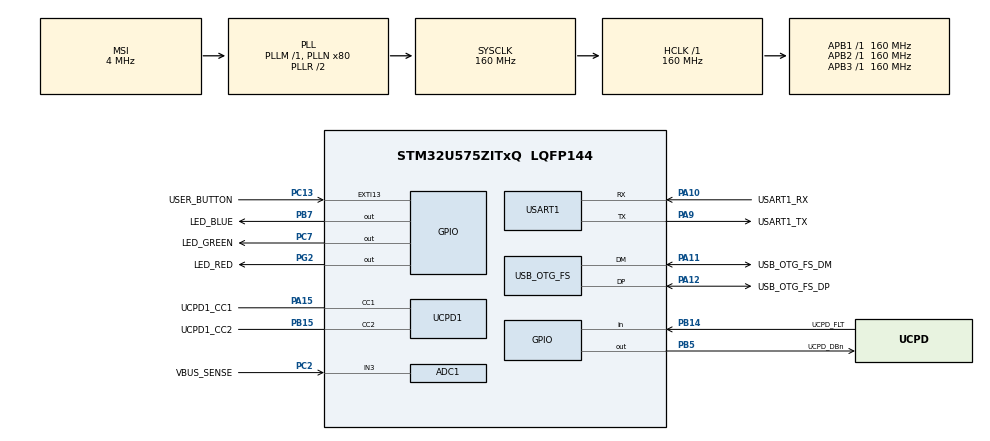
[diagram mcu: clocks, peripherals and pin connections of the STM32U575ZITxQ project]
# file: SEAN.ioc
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ADC1.NbrOfConversion=1
ADC1.Resolution=ADC_RESOLUTION_14B
ADC1.master=1
CORTEX_M33_NS.userName=CORTEX_M33
Mcu.Family=STM32U5
Mcu.Name=STM32U575ZITxQ
Mcu.Package=LQFP144
NVIC.OTG_FS_IRQn=true\:0\:0\:false\:false\:true\:false\:true\:true\:true
NVIC.PriorityGroup=NVIC_PRIORITYGROUP_3
NVIC.TIM1_UP_IRQn=true\:7\:0\:false\:false\:true\:false\:false\:true\:true
NVIC.TIM4_IRQn=true\:0\:0\:false\:false\:true\:false\:true\:true\:true
NVIC.TimeBase=TIM1_UP_IRQn
NVIC.TimeBaseIP=TIM1
PA10.GPIO_Label=USART1_RX
PA10.GPIO_PuPd=GPIO_PULLDOWN
PA10.GPIO_Speed=GPIO_SPEED_FREQ_VERY_HIGH
PA10.Mode=Asynchronous
PA10.Signal=USART1_RX
PA11.GPIO_Label=USB_OTG_FS_DM
PA11.GPIO_Speed=GPIO_SPEED_FREQ_VERY_HIGH
PA11.Mode=Device_Only
PA11.Signal=USB_OTG_FS_DM
PA12.GPIO_Label=USB_OTG_FS_DP
PA12.GPIO_Speed=GPIO_SPEED_FREQ_VERY_HIGH
PA12.Mode=Device_Only
PA12.Signal=USB_OTG_FS_DP
PA13\ (JTMS/SWDIO).Mode=Trace_Asynchronous_SW
PA13\ (JTMS/SWDIO).Signal=DEBUG_JTMS-SWDIO
PA14\ (JTCK/SWCLK).Mode=Trace_Asynchronous_SW
PA14\ (JTCK/SWCLK).Signal=DEBUG_JTCK-SWCLK
PA15\ (JTDI).GPIO_Label=UCPD1_CC1
PA15\ (JTDI).Mode=Sink_AllSignals
PA15\ (JTDI).Signal=UCPD1_CC1
PA9.GPIO_Label=USART1_TX
PA9.GPIO_PuPd=GPIO_PULLDOWN
PA9.GPIO_Speed=GPIO_SPEED_FREQ_VERY_HIGH
PA9.Mode=Asynchronous
PA9.Signal=USART1_TX
PB14.GPIO_Label=UCPD_FLT
PB14.Signal=GPIO_Input
PB15.GPIO_Label=UCPD1_CC2
PB15.Mode=Sink_AllSignals
PB15.Signal=UCPD1_CC2
PB3\ (JTDO/TRACESWO).Mode=Trace_Asynchronous_SW
PB3\ (JTDO/TRACESWO).Signal=DEBUG_JTDO-SWO
PB5.GPIO_Label=UCPD_DBn
PB5.Signal=GPIO_Output
PB7.GPIO_Label=LED_BLUE
PB7.GPIO_ModeDefaultOutputPP=GPIO_MODE_OUTPUT_PP
PB7.GPIO_PuPd=GPIO_PULLUP
PB7.GPIO_Speed=GPIO_SPEED_FREQ_HIGH
PB7.Signal=GPIO_Output
PC13.GPIO_Label=USER_BUTTON
PC13.GPIO_ModeDefaultEXTI=GPIO_MODE_IT_FALLING
PC13.Signal=GPXTI13
PC14-OSC32_IN\ (PC14).Mode=LSE-External-Oscillator
PC14-OSC32_IN\ (PC14).Signal=RCC_OSC32_IN
PC15-OSC32_OUT\ (PC15).Mode=LSE-External-Oscillator
PC15-OSC32_OUT\ (PC15).Signal=RCC_OSC32_OUT
PC2.GPIO_Label=VBUS_SENSE
PC2.Mode=IN3-Single-Ended
PC2.Signal=ADC1_IN3
PC7.GPIO_Label=LED_GREEN
PC7.GPIO_PuPd=GPIO_PULLUP
PC7.GPIO_Speed=GPIO_SPEED_FREQ_HIGH
PC7.Signal=GPIO_Output
PG2.GPIO_Label=LED_RED
PG2.GPIO_ModeDefaultOutputPP=GPIO_MODE_OUTPUT_PP
PG2.GPIO_PuPd=GPIO_PULLUP
PG2.GPIO_Speed=GPIO_SPEED_FREQ_HIGH
PG2.Signal=GPIO_Output
PWR.PowerMode=PWR_SMPS_SUPPLY
ProjectManager.HeapSize=0x200
ProjectManager.StackSize=0x400
ProjectManager.TargetToolchain=STM32CubeIDE
RCC.ADCFreq_Value=16000000
RCC.AHBFreq_Value=160000000
RCC.APB1Freq_Value=160000000
RCC.APB1TimFreq_Value=160000000
RCC.APB2Freq_Value=160000000
RCC.APB2TimFreq_Value=160000000
RCC.APB3Freq_Value=160000000
RCC.CortexFreq_Value=160000000
RCC.DACCLockSelectionVirtual=RCC_DAC1CLKSOURCE_LSI
RCC.DACCLockSelectionVirtualString=RCC_DAC1CLKSOURCE_LSI
RCC.EPOD_VALUE=4000000
RCC.HCLKFreq_Value=160000000
RCC.HSE_VALUE=16000000
RCC.HSI48_VALUE=48000000
RCC.HSI_VALUE=16000000
RCC.LSIDIV_VALUE=32000
RCC.MSI_VALUE=4000000
RCC.PLLN=80
RCC.SYSCLKFreq_VALUE=160000000
RCC.SYSCLKSource=RCC_SYSCLKSOURCE_PLLCLK
RCC.USBFreq_Value=48000000
RCC.VCOOutputFreq_Value=320000000
TIM4.PeriodNoDither=9999
TIM4.Prescaler=7999
USART1.VirtualMode-Asynchronous=VM_ASYNC
USB_OTG_FS.VirtualMode=Device_Only
VP_ICACHE_VS_ICACHE.Mode=DefaultMode
VP_LPBAMQUEUE_VS_QUEUE.Mode=QUEUEMODE
VP_LPBAM_VS_SIG1.Mode=SmartRun
VP_LPBAM_VS_SIG4.Mode=LPDMA1
VP_NETXDUO_VS_AddonsOoDHCP.Mode=Addons_DHCP_Client
VP_NETXDUO_VS_AddonsOoMQTT.Mode=Addons_MQTT
VP_NETXDUO_VS_Crypto.Mode=Crypto
VP_NETXDUO_VS_CustomOoInterface.Mode=Custom_Interface
VP_NETXDUO_VS_NXOoCore.Mode=NX_Core
VP_NETXDUO_VS_TLS.Mode=TLS
VP_PWR_VS_DBSignals.Mode=DisableDeadBatterySignals
VP_PWR_VS_LPOM.Mode=PowerOptimisation
VP_PWR_VS_SECSignals.Mode=Security/Privilege
VP_SYS_VS_tim1.Mode=TIM1
VP_THREADX_VS_RTOSJjThreadXJjCoreJjDefault.Mode=Core_Default
VP_THREADX_VS_RTOSJjThreadXJjPerformance_InfoJjDefault.Mode=Performance_Default
VP_THREADX_VS_RTOSJjThreadXJjTraceX_SupportJjDefault.Mode=TraceX_Support_Default
VP_TIM4_VS_ClockSourceINT.Mode=Internal
board=NUCLEO-U575ZI-Q

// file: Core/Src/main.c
/* USER CODE BEGIN Header */
/**
  ******************************************************************************
  * @file           : main.c
  * @brief          : Main program body
  ******************************************************************************
  * @attention
  *
  * Copyright (c) 2022 STMicroelectronics.
  * All rights reserved.
  *
  * This software is licensed under terms that can be found in the LICENSE file
  * in the root directory of this software component.
  * If no LICENSE file comes with this software, it is provided AS-IS.
  *
  ******************************************************************************
  */
/* USER CODE END Header */
#include "main.h"
#include "app_threadx.h"
#include "adc.h"
#include "icache.h"
#include "tim.h"
#include "ucpd.h"
#include "usart.h"
#include "usb_otg.h"
#include "gpio.h"

/* USER CODE BEGIN Includes */
#include <stdio.h>
/* USER CODE END Includes */

void SystemClock_Config(void);
static void SystemPower_Config(void);

/* USER CODE BEGIN 0 */
#ifdef __GNUC__
#define PUTCHAR_PROTOTYPE int __io_putchar(int ch)
#else
#define PUTCHAR_PROTOTYPE int fputc(int ch, FILE *f)
#endif

PUTCHAR_PROTOTYPE
{
	HAL_UART_Transmit(&huart1, (uint8_t *)&ch, 1, 0xFFFF);
	return ch;
}
/* USER CODE END 0 */

int main(void)
{

  /* MCU Configuration--------------------------------------------------------*/

  /* Reset of all peripherals, Initializes the Flash interface and the Systick. */
  HAL_Init();

  /* Configure the system clock */
  SystemClock_Config();

  /* Configure the System Power */
  SystemPower_Config();

  /* Initialize all configured peripherals */
  MX_GPIO_Init();
  MX_ADC1_Init();
  MX_UCPD1_Init();
  MX_USART1_UART_Init();
  MX_USB_OTG_FS_PCD_Init();
  MX_ICACHE_Init();
  MX_TIM4_Init();
  /* USER CODE BEGIN 2 */
  HAL_TIM_Base_Start_IT(&htim4);
  printf("initiate driver successfully\r\n");
  /* USER CODE END 2 */

  MX_ThreadX_Init();

  /* We should never get here as control is now taken by the scheduler */
  /* Infinite loop */
  while (1)
  {

  }
}

void SystemClock_Config(void)
{
  RCC_OscInitTypeDef RCC_OscInitStruct = {0};
  RCC_ClkInitTypeDef RCC_ClkInitStruct = {0};

  /** Configure the main internal regulator output voltage
  */
  if (HAL_PWREx_ControlVoltageScaling(PWR_REGULATOR_VOLTAGE_SCALE1) != HAL_OK)
  {
    Error_Handler();
  }

  /** Initializes the CPU, AHB and APB busses clocks
  */
  RCC_OscInitStruct.OscillatorType = RCC_OSCILLATORTYPE_HSI48|RCC_OSCILLATORTYPE_HSI
                              |RCC_OSCILLATORTYPE_MSI;
  RCC_OscInitStruct.HSIState = RCC_HSI_ON;
  RCC_OscInitStruct.HSI48State = RCC_HSI48_ON;
  RCC_OscInitStruct.HSICalibrationValue = RCC_HSICALIBRATION_DEFAULT;
  RCC_OscInitStruct.MSIState = RCC_MSI_ON;
  RCC_OscInitStruct.MSICalibrationValue = RCC_MSICALIBRATION_DEFAULT;
  RCC_OscInitStruct.MSIClockRange = RCC_MSIRANGE_4;
  RCC_OscInitStruct.PLL.PLLState = RCC_PLL_ON;
  RCC_OscInitStruct.PLL.PLLSource = RCC_PLLSOURCE_MSI;
  RCC_OscInitStruct.PLL.PLLMBOOST = RCC_PLLMBOOST_DIV1;
  RCC_OscInitStruct.PLL.PLLM = 1;
  RCC_OscInitStruct.PLL.PLLN = 80;
  RCC_OscInitStruct.PLL.PLLP = 2;
  RCC_OscInitStruct.PLL.PLLQ = 2;
  RCC_OscInitStruct.PLL.PLLR = 2;
  RCC_OscInitStruct.PLL.PLLRGE = RCC_PLLVCIRANGE_0;
  RCC_OscInitStruct.PLL.PLLFRACN = 0;
  if (HAL_RCC_OscConfig(&RCC_OscInitStruct) != HAL_OK)
  {
    Error_Handler();
  }

  /** Initializes the CPU, AHB and APB busses clocks
  */
  RCC_ClkInitStruct.ClockType = RCC_CLOCKTYPE_HCLK|RCC_CLOCKTYPE_SYSCLK
                              |RCC_CLOCKTYPE_PCLK1|RCC_CLOCKTYPE_PCLK2
                              |RCC_CLOCKTYPE_PCLK3;
  RCC_ClkInitStruct.SYSCLKSource = RCC_SYSCLKSOURCE_PLLCLK;
  RCC_ClkInitStruct.AHBCLKDivider = RCC_SYSCLK_DIV1;
  RCC_ClkInitStruct.APB1CLKDivider = RCC_HCLK_DIV1;
  RCC_ClkInitStruct.APB2CLKDivider = RCC_HCLK_DIV1;
  RCC_ClkInitStruct.APB3CLKDivider = RCC_HCLK_DIV1;

  if (HAL_RCC_ClockConfig(&RCC_ClkInitStruct, FLASH_LATENCY_4) != HAL_OK)
  {
    Error_Handler();
  }
}

/**
  * @brief Power Configuration
  * @retval None
  */
static void SystemPower_Config(void)
{
  HAL_PWREx_EnableVddIO2();

  /*
   * Switch to SMPS regulator instead of LDO
   */
  if (HAL_PWREx_ConfigSupply(PWR_SMPS_SUPPLY) != HAL_OK)
  {
    Error_Handler();
  }
}

void HAL_TIM_PeriodElapsedCallback(TIM_HandleTypeDef *htim)
{
  if (htim->Instance == TIM1) {
    HAL_IncTick();
  }
}

void Error_Handler(void)
{
  __disable_irq();
  while (1)
  {
  }
}
